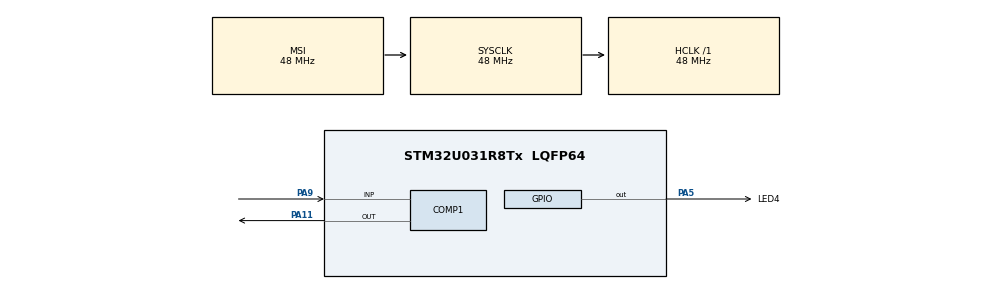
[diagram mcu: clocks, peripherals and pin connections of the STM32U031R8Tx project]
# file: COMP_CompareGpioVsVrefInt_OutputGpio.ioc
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COMP1.Hysteresis=COMP_HYSTERESIS_MEDIUM
Mcu.Family=STM32U0
Mcu.Name=STM32U031R8Tx
Mcu.Package=LQFP64
PA11\ [PA9].Mode=ExternalOutput
PA11\ [PA9].Signal=COMP1_OUT
PA5.GPIO_Label=LED4
PA5.Signal=GPIO_Output
PA9.Mode=INP
PA9.Signal=COMP1_INP
ProjectManager.HeapSize=0x200
ProjectManager.StackSize=0x400
ProjectManager.TargetToolchain=EWARM V9.20
RCC.ADCFreq_Value=48000000
RCC.AHBFreq_Value=48000000
RCC.CortexFreq_Value=48000000
RCC.HCLKFreq_Value=48000000
RCC.HSE_VALUE=4000000
RCC.HSI48_VALUE=48000000
RCC.HSI_VALUE=16000000
RCC.LSE_VALUE=32768
RCC.MSIClockRangeVal=RCC_MSIRANGE_11
RCC.MSI_VALUE=48000000
RCC.SYSCLKFreq_VALUE=48000000
RCC.SYSCLKSource=RCC_SYSCLKSOURCE_MSI
RCC.VCOOutputFreq_Value=64000000
VP_COMP1_VS_VREFINT.Mode=VREFINT
VP_PWR_VS_SECSignals.Mode=Security/Privilege
board=NUCLEO-U031R8

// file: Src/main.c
/* USER CODE BEGIN Header */
/**
  ******************************************************************************
  * @file    Examples/COMP/COMP_CompareGpioVsVrefInt_OutputGpio/Src/main.c
  * @author  MCD Application Team
  * @brief   How to use a comparator peripheral to compare a voltage level
  *          on a GPIO pin versus the internal voltage reference (VrefInt)
  *          with comparator output connected to a GPIO pin.
  *          This example is based on the STM32U0xx COMP HAL API.
  ******************************************************************************
  * @attention
  *
  * Copyright (c) 2023 STMicroelectronics.
  * All rights reserved.
  *
  * This software is licensed under terms that can be found in the LICENSE file
  * in the root directory of this software component.
  * If no LICENSE file comes with this software, it is provided AS-IS.
  *
  ******************************************************************************
  */
/* USER CODE END Header */
#include "main.h"

COMP_HandleTypeDef hcomp1;

void SystemClock_Config(void);
static void MX_GPIO_Init(void);
static void MX_COMP1_Init(void);

int main(void)
{

  /* MCU Configuration--------------------------------------------------------*/

  /* Reset of all peripherals, Initializes the Flash interface and the Systick. */
  HAL_Init();

  /* Configure the system clock */
  SystemClock_Config();

  /* Initialize all configured peripherals */
  MX_GPIO_Init();
  MX_COMP1_Init();
  /* USER CODE BEGIN 2 */
  BSP_LED_Init(LED4);

  /* Start comparator */
  if(HAL_COMP_Start(&hcomp1) != HAL_OK)
  {
    /* Initialization Error */
    Error_Handler();
  }

  /* Lock comparator instance */
  /* Note: Comparator lock is optional, to protect against any unexpected
           program action on comparator configuration
           (for example, due to program counter corruption). */
  //HAL_COMP_Lock(&hcomp1);

  /* USER CODE END 2 */

  /* Infinite loop */
  /* USER CODE BEGIN WHILE */
  while (1)
  {
    /* Set LED state in function of state of GPIO connected to                */
    /* comparator output.                                                     */
    /* Note: State of GPIO is monitored for the purpose of this example.      */
    /*       An alternate solution is to monitor directly comparator output   */
    /*       using function "HAL_COMP_GetOutputLevel()".                      */
    if (HAL_GPIO_ReadPin(GPIOA, GPIO_PIN_11) != 0)
    {
      BSP_LED_On(LED4);
    }
    else
    {
      BSP_LED_Off(LED4);
    }

    /* USER CODE END WHILE */

  }
}

void SystemClock_Config(void)
{
  RCC_OscInitTypeDef RCC_OscInitStruct = {0};
  RCC_ClkInitTypeDef RCC_ClkInitStruct = {0};

  /** Configure the main internal regulator output voltage
  */
  HAL_PWREx_ControlVoltageScaling(PWR_REGULATOR_VOLTAGE_SCALE1);

  /** Initializes the RCC Oscillators according to the specified parameters
  * in the RCC_OscInitTypeDef structure.
  */
  RCC_OscInitStruct.OscillatorType = RCC_OSCILLATORTYPE_MSI;
  RCC_OscInitStruct.MSIState = RCC_MSI_ON;
  RCC_OscInitStruct.MSICalibrationValue = RCC_MSICALIBRATION_DEFAULT;
  RCC_OscInitStruct.MSIClockRange = RCC_MSIRANGE_11;
  RCC_OscInitStruct.PLL.PLLState = RCC_PLL_NONE;
  if (HAL_RCC_OscConfig(&RCC_OscInitStruct) != HAL_OK)
  {
    Error_Handler();
  }

  /** Initializes the CPU, AHB and APB buses clocks
  */
  RCC_ClkInitStruct.ClockType = RCC_CLOCKTYPE_HCLK|RCC_CLOCKTYPE_SYSCLK
                              |RCC_CLOCKTYPE_PCLK1;
  RCC_ClkInitStruct.SYSCLKSource = RCC_SYSCLKSOURCE_MSI;
  RCC_ClkInitStruct.AHBCLKDivider = RCC_SYSCLK_DIV1;
  RCC_ClkInitStruct.APB1CLKDivider = RCC_HCLK_DIV1;

  if (HAL_RCC_ClockConfig(&RCC_ClkInitStruct, FLASH_LATENCY_1) != HAL_OK)
  {
    Error_Handler();
  }
}

static void MX_COMP1_Init(void)
{

  hcomp1.Instance = COMP1;
  hcomp1.Init.InputPlus = COMP_INPUT_PLUS_IO4;
  hcomp1.Init.InputMinus = COMP_INPUT_MINUS_VREFINT;
  hcomp1.Init.OutputPol = COMP_OUTPUTPOL_NONINVERTED;
  hcomp1.Init.Hysteresis = COMP_HYSTERESIS_MEDIUM;
  hcomp1.Init.BlankingSrce = COMP_BLANKINGSRC_NONE;
  hcomp1.Init.Mode = COMP_POWERMODE_HIGHSPEED;
  hcomp1.Init.TriggerMode = COMP_TRIGGERMODE_NONE;
  if (HAL_COMP_Init(&hcomp1) != HAL_OK)
  {
    Error_Handler();
  }

}

static void MX_GPIO_Init(void)
{
  GPIO_InitTypeDef GPIO_InitStruct = {0};

  /* GPIO Ports Clock Enable */
  __HAL_RCC_GPIOA_CLK_ENABLE();

  /*Configure GPIO pin Output Level */
  HAL_GPIO_WritePin(LED4_GPIO_Port, LED4_Pin, GPIO_PIN_RESET);

  /*Configure GPIO pin : LED4_Pin */
  GPIO_InitStruct.Pin = LED4_Pin;
  GPIO_InitStruct.Mode = GPIO_MODE_OUTPUT_PP;
  GPIO_InitStruct.Pull = GPIO_NOPULL;
  GPIO_InitStruct.Speed = GPIO_SPEED_FREQ_LOW;
  HAL_GPIO_Init(LED4_GPIO_Port, &GPIO_InitStruct);

}

void Error_Handler(void)
{
  /* USER CODE BEGIN Error_Handler_Debug */
  /* User can add his own implementation to report the HAL error return state */

  /* Turn on LED and remain in infinite loop */
  while (1)
  {
    BSP_LED_On(LED4);
  }
  /* USER CODE END Error_Handler_Debug */
}
